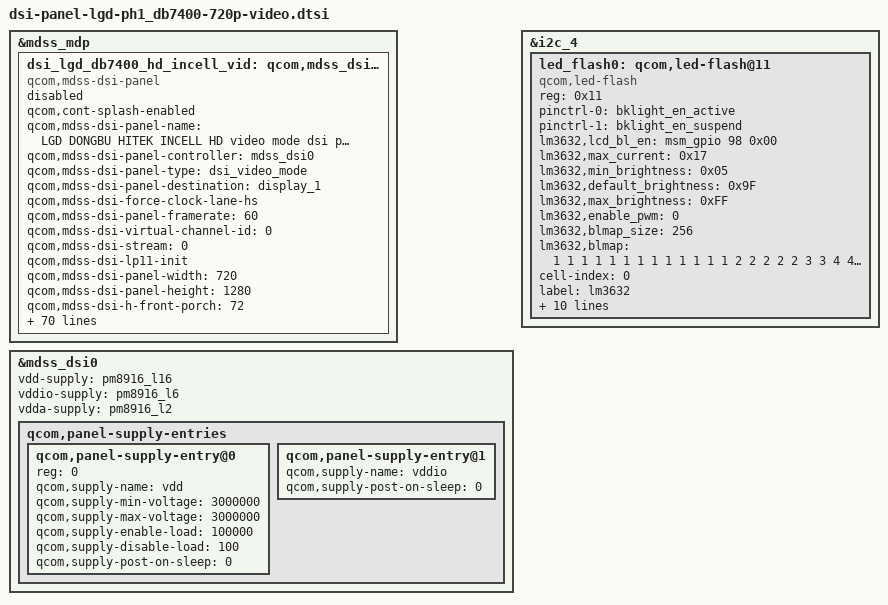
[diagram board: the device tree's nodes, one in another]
&mdss_mdp {
	dsi_lgd_db7400_hd_incell_vid: qcom,mdss_dsi_lgd_incell_db7400_hd_video{
		compatible = "qcom,mdss-dsi-panel";
		status = "disable";
		qcom,cont-splash-enabled;
		qcom,mdss-dsi-panel-name = "LGD DONGBU HITEK INCELL HD video mode dsi panel";
		qcom,mdss-dsi-panel-controller = <&mdss_dsi0>;
		qcom,mdss-dsi-panel-type = "dsi_video_mode";
		qcom,mdss-dsi-panel-destination = "display_1";
		qcom,mdss-dsi-force-clock-lane-hs;
		qcom,mdss-dsi-panel-framerate = <60>;
		qcom,mdss-dsi-virtual-channel-id = <0>;
		qcom,mdss-dsi-stream = <0>;
		qcom,mdss-dsi-lp11-init;
		qcom,mdss-dsi-panel-width = <720>;
		qcom,mdss-dsi-panel-height = <1280>;
		qcom,mdss-dsi-h-front-porch = <72>;
		qcom,mdss-dsi-h-back-porch = <120>;
		qcom,mdss-dsi-h-pulse-width = <4>;
		qcom,mdss-dsi-h-sync-skew = <0>;
		qcom,mdss-dsi-v-front-porch = <580>;
		qcom,mdss-dsi-v-back-porch = <11>;
		qcom,mdss-dsi-v-pulse-width = <1>;
		qcom,mdss-dsi-h-left-border = <0>;
		qcom,mdss-dsi-h-right-border = <0>;
		qcom,mdss-dsi-v-top-border = <0>;
		qcom,mdss-dsi-v-bottom-border = <0>;
		qcom,mdss-pan-physical-width-dimension = < 71 >;
		qcom,mdss-pan-physical-height-dimension = < 126 >;
		qcom,mdss-dsi-bpp = <24>;
		qcom,mdss-dsi-color-order = "rgb_swap_rgb";
		qcom,mdss-dsi-underflow-color = <0>;
		qcom,mdss-dsi-border-color = <0>;

		/* DB7400 CUT5 Initial code start */
		qcom,mdss-dsi-on-command-cut5 = [
			15 01 00 00 00 00 02 /*address*/
			36 00

			15 01 00 00 00 00 02 /*manufacturer*/
			B0 00

			29 01 00 00 00 00 03 /*RGB interface*/
			B1 00 30

			29 01 00 00 00 00 07 /*module charateristic set*/
			B2 50 00 0C 00 00 00

			29 01 00 00 00 00 05 /*internal timgin set*/
			B3 4F 80 32 56

			29 01 00 00 00 00 07/*channel control*/
			B4 05 04 02 00 11 00

			29 01 00 00 00 00 34 /*GIP Control Set*/
			B5 19 04 1C 22 2F 80
			2F 1F 04 40 05 00 20
			09 04 40 05 00 A5 0D
			2F 28 3F FF 3F FF 01
			7C 00 02 50 23 40 15
			6C CB BA A9 97 8D 1F
			23 40 15 6C CB BA A9
			97 8D 1F

			29 01 00 00 00 00 03 /*touch enable*/
			B6 01 01

			29 01 00 00 00 00 04 /*gvddp*/
			B7 00 3C 3E

			29 01 00 00 00 00 03 /*vcom*/
			BA 00 43

			29 01 00 00 00 00 10 /*vghl*/
			BB 00 94 8B 00 00 00
			00 00 00 00 00 00 00
			00 13

			29 01 00 00 00 00 03
			BD 04 33

			15 01 00 00 00 00 02 /*vci1*/
			BE 44

			29 01 00 00 00 00 07 /*write dsi control*/
			95 00 08 10 00 00 00

			29 01 00 00 00 00 03 /*mipi parameter setting*/
			C6 0A 00

			29 01 00 00 00 00 02 /*add temp*/
			CF 07

			29 01 00 00 00 00 1B /*touch gip control*/
			D7 01 13 FF 39 0B 04
			14 F4 01 00 00 00 00
			40 01 57 57 2F 28 28
			50 00 00 00 00 00

			29 01 00 00 00 00 06
			F5 00 06 00 00 80

			29 01 00 00 00 00 02 /*vdd1 regulator*/
			F6 06

			29 01 00 00 00 00 04/*sharpness enhance*/
			81 18 34 00

			29 01 00 00 00 00 22/*contrast enhance*/
			83 10 00 07 0F 17 1F
			27 2F 37 3F 47 4F 57
			5F 67 6F 77 7F 87 8F
			97 9F A7 AF B7 BF C7
			CF D7 DF E7 EF F5

			29 01 00 00 00 00 24/*power sequence control*/
			F0 18 00 00 14 00 00
			00 01 00 03 2B 01 02
			53 58 5D 62 A6 AB B0
			B0 B0 AF B0 AD 85 B0
			B0 5D 58 53 4E 0A 05
			00

			29 01 00 00 00 00 0A /*pos gamma curve red*/
			D0 63 04 72 03 00 00
			42 01 02

			29 01 00 00 00 00 0A /*neg gamma curve red*/
			D1 62 03 73 02 00 00
			42 12 01

			29 01 00 00 00 00 0A /*pos gamma curve green*/
			D2 53 04 72 03 00 00
			42 01 02

			29 01 00 00 00 00 0A /*neg gamma curve green*/
			D3 52 03 73 02 00 00
			42 12 01

			29 01 00 00 00 00 0A /*pos gamma curve blue*/
			D4 53 04 72 03 00 00
			42 01 02

			29 01 00 00 3C 00 0A /*neg gamma curve blue*/
			D5 52 03 73 02 00 00
			42 12 01

			05 01 00 00 A0 00 01 /*exit sleep*/
			11

			05 01 00 00 28 00 01 /*display on*/
			29

		];

		qcom,mdss-dsi-off-command1-cut5 = [
			05 01 00 00 28 00 01 /*display off*/
			28
			05 01 00 00 28 00 01 /*Sleep in*/
			10
		];
		qcom,mdss-dsi-off-command2-cut5 = [
			29 01 00 00 00 00 1C /*34->1C GIP Control Set*/
			B5 19 04 1C 22 2F 80
			2F 1F 04 40 05 00 20
			09 04 40 05 00 A5 0D
			2F 1F 04 00 04 00 00
			29 01 00 00 00 00 03 /*touch enable*/
			B6 01 01

			29 01 00 00 00 00 02 /*add temp*/
			CF 07

			29 01 00 00 00 00 1B /*touch gip control*/
			D7 01 13 FF 39 0B 04
			14 F4 01 00 00 00 00
			40 01 67 67 47 10 10
			34 00 00 00 00 00

			29 01 00 00 00 00 06/*Touch LFD Control set*/
			F5 00 06 00 00 C0

			29 01 00 00 5A 00 03 /*mipi lane floating*/
			C8 01 00
		];
		/* DB7400 CUT5 initial code end */

		/* DB7400 CUT6 initial code start */
		qcom,mdss-dsi-on-command-cut6 = [
			15 01 00 00 00 00 02 /*address*/
			36 00

			15 01 00 00 00 00 02 /*manufacturer*/
			B0 00

			29 01 00 00 00 00 03 /*RGB interface*/
			B1 00 30

			29 01 00 00 00 00 07 /*module charateristic set*/
			B2 50 00 0C 00 00 00

			29 01 00 00 00 00 05 /*internal timgin set*/
			B3 4F 80 32 56

			29 01 00 00 00 00 07/*channel control*/
			B4 05 04 0A 00 11 00

			29 01 00 00 00 00 37 /*GIP Control Set*/
			B5 19 04 1C 22 2F 80
			2F 1F 04 40 05 05 00
			20 09 04 40 05 05 00
			A5 0D 2F 28 3F FF 3F
			FF 01 7C 00 03 78 23
			40 15 6C CB BA A9 97
			8D 1F 23 40 15 6C CB
			BA A9 97 8D 1F 00

			29 01 00 00 00 00 03 /*touch enable*/
			B6 01 01

			29 01 00 00 00 00 04 /*gvddp*/
			B7 00 3C 3E

			29 01 00 00 00 00 03 /*vcom*/
			BA 00 43

			29 01 00 00 00 00 10 /*vghl*/
			BB 00 94 8B 00 00 00
			00 00 00 00 00 00 00
			00 13

			29 01 00 00 00 00 03 /*Bias current*/
			BD 03 31

			15 01 00 00 00 00 02 /*vci1*/
			BE 44

			29 01 00 00 00 00 07 /*write dsi control*/
			95 00 08 10 00 00 00

			29 01 00 00 00 00 03 /*mipi parameter setting*/
			C6 08 00

			29 01 00 00 00 00 02 /*add temp*/
			CF 07

			29 01 00 00 00 00 1B /*touch gip control*/
			D7 00 03 FF 00 00 04
			14 CC 01 00 00 00 00
			40 01 57 57 16 28 28
			69 00 00 00 00 00

			15 01 00 00 00 00 02 /*Contrast of*/
			83 00

			39 01 00 00 00 00 2F /*ief 1*/
			77 03 00 00 00 11 05
			10 d1 0b 20 ee 05 20
			b2 18 30 11 05 50 d1
			0b 60 b2 18 70 b2 18
			70 b2 18 70 b2 18 70
			b2 18 70 b2 18 70 b2
			18 70 b2 18 70

			39 01 00 00 00 00 42 /*ief 2*/
			78 25 29 ff fd e1 5f
			91 fe db ff fb 2d 01
			25 81 3e 03 e0 bf 10
			03 d8 1f 09 c3 00 1d
			71 ff fd db 8f 91 fe
			77 e0 f6 2d 01 25 29
			ff fd e1 5f 91 fe db
			ff fb 2d 01 25 29 ff
			fd e1 5f 91 fe db ff
			fb 2d 01

			39 01 00 00 00 00 42 /*ief 3*/
			79 25 29 ff fd e1 5f
			91 fe db ff fb 2d 01
			25 29 ff fd e1 5f 91
			fe db ff fb 2d 01 25
			29 ff fd e1 5f 91 fe
			db ff fb 2d 01 25 29
			ff fd e1 5f 91 fe db
			ff fb 2d 01 25 29 ff
			fd e1 5f 91 fe db ff
			fb 2d 01

			39 01 00 00 00 00 46 /*ief 4*/
			7a 25 29 ff fd e1 5f
			91 fe db ff fb 2d 01
			25 29 ff fd e1 5f 91
			fe db ff fb 2d 01 25
			29 ff fd e1 5f 91 fe
			db ff fb 2d 01 25 29
			ff fd e1 5f 91 fe db
			ff fb 2d 01 00 00 00
			00 00 00 00 00 00 00
			00 00 00 80 00 00 00

			29 01 00 00 00 00 06 /*DB Check need*/
			F5 00 06 00 00 80

			29 01 00 00 00 00 02 /*vdd1 regulator*/
			F6 06

			29 01 00 00 00 00 24/*power sequence control*/
			F0 18 00 00 14 00 00
			00 01 00 03 2B 01 02
			53 58 5D 62 A6 AB B0
			B0 B0 AF B0 AD 85 B0
			B0 5D 58 53 4E 0A 05
			00

			29 01 00 00 00 00 0A /*pos gamma curve red*/
			D0 63 04 72 03 00 00
			42 01 02

			29 01 00 00 00 00 0A /*neg gamma curve red*/
			D1 62 03 73 02 00 00
			42 12 01

			29 01 00 00 00 00 0A /*pos gamma curve green*/
			D2 53 04 72 03 00 00
			42 01 02

			29 01 00 00 00 00 0A /*neg gamma curve green*/
			D3 52 03 73 02 00 00
			42 12 01

			29 01 00 00 00 00 0A /*pos gamma curve blue*/
			D4 53 04 72 03 00 00
			42 01 02

			29 01 00 00 3C 00 0A /*neg gamma curve blue*/
			D5 52 03 73 02 00 00
			42 12 01

			05 01 00 00 A0 00 01 /*exit sleep*/
			11

			05 01 00 00 28 00 01 /*display on*/
			29

		];
		qcom,mdss-dsi-off-command1-cut6 = [
			05 01 00 00 28 00 01 /*display off*/
			28
			05 01 00 00 28 00 01 /*Sleep in*/
			10
		];
		qcom,mdss-dsi-off-command2-cut6 = [
			29 01 00 00 00 00 1E /*34->1C GIP Control Set*/
			B5 19 04 1C 22 2F 80
			2F 1F 04 40 05 05 00
			20 09 04 40 05 05 00
			A5 0D 2F 1F 04 00 04
			00 00

			29 01 00 00 00 00 06/*Touch LFD Control set*/
			F5 00 06 00 00 C0

			29 01 00 00 5A 00 03 /*mipi lane floating*/
			C8 01 00
		];
		/* DB7400 CUT6 initial code end */

		/* DB7400 CUT7 initial code start */
		qcom,mdss-dsi-on-command = [
			15 01 00 00 00 00 02 /*address*/
			36 00

			15 01 00 00 00 00 02 /*manufacturer*/
			B0 00

			29 01 00 00 00 00 03 /*RGB interface*/
			B1 00 30

			29 01 00 00 00 00 07 /*module charateristic set*/
			B2 50 00 0C 00 00 00

			29 01 00 00 00 00 05 /*internal timgin set*/
			B3 4F 80 32 56

			29 01 00 00 00 00 07/*channel control*/
			B4 05 04 0A 00 11 00

			29 01 00 00 00 00 37 /*GIP Control Set*/
			B5 19 04 1C 22 2F 80
			2F 1F 04 40 05 05 00
			20 09 04 40 05 05 00
			A5 0D 2F 28 3F FF 3F
			FF 01 7C 00 03 78 23
			40 15 6C CB BA A9 97
			8D 1F 23 40 15 6C CB
			BA A9 97 8D 1F 00

			29 01 00 00 00 00 03 /*touch enable*/
			B6 01 01

			29 01 00 00 00 00 04 /*gvddp*/
			B7 00 3C 3E

			29 01 00 00 00 00 03 /*vcom*/
			BA 00 43

			29 01 00 00 00 00 10 /*vghl*/
			BB 00 94 8B 00 00 00
			00 00 00 00 00 00 00
			00 13

			29 01 00 00 00 00 03 /*Bias current*/
			BD 03 31

			15 01 00 00 00 00 02 /*vci1*/
			BE 44

			29 01 00 00 00 00 07 /*write dsi control*/
			95 00 08 10 00 00 00

			29 01 00 00 00 00 03 /*mipi parameter setting*/
			C6 08 00

			29 01 00 00 00 00 02 /*add temp*/
			CF 07

			29 01 00 00 00 00 1B /*touch gip control*/
			D7 00 03 FF 00 00 04
			14 CC 01 00 00 00 00
			40 01 57 57 16 28 28
			69 00 00 00 00 00

			15 01 00 00 00 00 02 /*Contrast of*/
			83 00

			39 01 00 00 00 00 2F /*ief 1*/
			77 03 00 00 00 11 05
			10 d1 0b 20 ee 05 20
			b2 18 30 11 05 50 d1
			0b 60 b2 18 70 b2 18
			70 b2 18 70 b2 18 70
			b2 18 70 b2 18 70 b2
			18 70 b2 18 70

			39 01 00 00 00 00 42 /*ief 2*/
			78 25 29 ff fd e1 5f
			91 fe db ff fb 2d 01
			25 81 3e 03 e0 bf 10
			03 d8 1f 09 c3 00 1d
			71 ff fd db 8f 91 fe
			77 e0 f6 2d 01 25 29
			ff fd e1 5f 91 fe db
			ff fb 2d 01 25 29 ff
			fd e1 5f 91 fe db ff
			fb 2d 01

			39 01 00 00 00 00 42 /*ief 3*/
			79 25 29 ff fd e1 5f
			91 fe db ff fb 2d 01
			25 29 ff fd e1 5f 91
			fe db ff fb 2d 01 25
			29 ff fd e1 5f 91 fe
			db ff fb 2d 01 25 29
			ff fd e1 5f 91 fe db
			ff fb 2d 01 25 29 ff
			fd e1 5f 91 fe db ff
			fb 2d 01

			39 01 00 00 00 00 46 /*ief 4*/
			7a 25 29 ff fd e1 5f
			91 fe db ff fb 2d 01
			25 29 ff fd e1 5f 91
			fe db ff fb 2d 01 25
			29 ff fd e1 5f 91 fe
			db ff fb 2d 01 25 29
			ff fd e1 5f 91 fe db
			ff fb 2d 01 00 00 00
			00 00 00 00 00 00 00
			00 00 00 80 00 00 00

			29 01 00 00 00 00 06 /* sharpness_control */
			81 00 22 00 04 04

			29 01 00 00 00 00 06 /*DB Check need*/
			F5 00 06 00 00 80

			29 01 00 00 00 00 02 /*vdd1 regulator*/
			F6 06

			29 01 00 00 00 00 24/*power sequence control*/
			F0 18 00 00 14 00 00
			00 01 00 03 2B 01 02
			53 58 5D 62 A6 AB B0
			B0 B0 AF B0 AD 85 B0
			B0 5D 58 53 4E 0A 05
			00

			29 01 00 00 00 00 0A /*pos gamma curve red*/
			D0 63 04 72 03 00 00
			42 01 02

			29 01 00 00 00 00 0A /*neg gamma curve red*/
			D1 62 03 73 02 00 00
			42 12 01

			29 01 00 00 00 00 0A /*pos gamma curve green*/
			D2 53 04 72 03 00 00
			42 01 02

			29 01 00 00 00 00 0A /*neg gamma curve green*/
			D3 52 03 73 02 00 00
			42 12 01

			29 01 00 00 00 00 0A /*pos gamma curve blue*/
			D4 53 04 72 03 00 00
			42 01 02

			29 01 00 00 3C 00 0A /*neg gamma curve blue*/
			D5 52 03 73 02 00 00
			42 12 01

			05 01 00 00 A0 00 01 /*exit sleep*/
			11

			05 01 00 00 28 00 01 /*display on*/
			29

		];
		qcom,mdss-dsi-off-command1 = [
			05 01 00 00 28 00 01 /*display off*/
			28
			05 01 00 00 28 00 01 /*Sleep in*/
			10
		];
		qcom,mdss-dsi-off-command2 = [
			29 01 00 00 00 00 1E /*34->1C GIP Control Set*/
			B5 19 04 1C 22 2F 80
			2F 1F 04 40 05 05 00
			20 09 04 40 05 05 00
			A5 0D 2F 1F 04 00 04
			00 00

			29 01 00 00 00 00 06/*Touch LFD Control set*/
			F5 00 06 00 00 C0

			29 01 00 00 5A 00 03 /*mipi lane floating*/
			C8 01 00
		];
		/* DB7400 CUT7 initial code end */

		/* reader mode command start */
		qcom,panel-reader-mode-step1-command = [
			29 01 00 00 00 00 0E /* reader mode 1 */
			89 10 FF FF E9 00 00
			00 FF FF DE 00 00 00
		];
		qcom,panel-reader-mode-step2-command = [
			29 01 00 00 00 00 0E /* reader mode 2 */
			89 10 FF FF DE 00 00
			00 FF FF DE 00 00 00
		];
		qcom,panel-reader-mode-step3-command = [
			29 01 00 00 00 00 0E /* reader mode 3 */
			89 10 FF FF CE 00 00
			00 FF FF DE 00 00 00
		];

		qcom,panel-reader-mode-off-command = [
			29 01 00 00 00 00 02 /* reader mode off */
			89 00
		];
		qcom,panel-reader-mode-mono-enable-command = [
			39 01 00 00 00 00 2F /*ief 1*/
			77 03 00 00 00 11 05
			10 D1 0B 20 EE 05 20
			B2 18 30 11 05 50 D1
			0B 60 B2 18 70 B2 18
			70 B2 18 70 B2 18 70
			B2 18 70 B2 18 70 B2
			18 70 B2 18 70

			39 01 00 00 00 00 42 /*ief 2*/
			78 59 B0 44 07 9C 60
			89 0E 98 C0 12 1D 00
			59 90 85 00 9C 90 89
			0D 98 60 08 71 00 63
			60 44 07 9C 50 89 0E
			18 C0 16 1D 00 4C 18
			45 07 98 70 89 0E 34
			E1 0D 1D 00 4C 18 45
			07 98 70 89 0E 34 E1
			0D 1D 00

			39 01 00 00 00 00 42 /*ief 3*/
			79 4D B0 84 0A 9A 60
			09 0F 30 C1 12 F7 07
			4D B0 84 0A 9A 60 09
			0F 30 C1 12 F7 07 4D
			B0 84 0A 9A 60 09 0F
			30 C1 12 F7 07 4D B0
			84 0A 9A 60 09 0F 30
			C1 12 F7 07 4D B0 84
			0A 9A 60 09 0F 30 C1
			12 F7 07

			39 01 00 00 00 00 46 /*ief 4*/
			7A 4D B0 84 0A 9A 60
			09 0F 30 C1 12 F7 07
			4D B0 84 0A 9A 60 09
			0F 30 C1 F7 07 00 4D
			B0 84 0A 9A 60 09 0F
			30 C1 12 F7 07 4D B0
			84 0A 9A 60 09 0F 30
			C1 12 F7 07 00 00 00
			00 00 00 00 00 00 00
			00 00 00 80 00 00 00
		];
		qcom,panel-reader-mode-mono-disable-command = [
			39 01 00 00 00 00 2F /*ief 1*/
			77 03 00 00 00 11 05
			10 d1 0b 20 ee 05 20
			b2 18 30 11 05 50 d1
			0b 60 b2 18 70 b2 18
			70 b2 18 70 b2 18 70
			b2 18 70 b2 18 70 b2
			18 70 b2 18 70

			39 01 00 00 00 00 42 /*ief 2*/
			78 25 29 ff fd e1 5f
			91 fe db ff fb 2d 01
			25 81 3e 03 e0 bf 10
			03 d8 1f 09 c3 00 1d
			71 ff fd db 8f 91 fe
			77 e0 f6 2d 01 25 29
			ff fd e1 5f 91 fe db
			ff fb 2d 01 25 29 ff
			fd e1 5f 91 fe db ff
			fb 2d 01

			39 01 00 00 00 00 42 /*ief 3*/
			79 25 29 ff fd e1 5f
			91 fe db ff fb 2d 01
			25 29 ff fd e1 5f 91
			fe db ff fb 2d 01 25
			29 ff fd e1 5f 91 fe
			db ff fb 2d 01 25 29
			ff fd e1 5f 91 fe db
			ff fb 2d 01 25 29 ff
			fd e1 5f 91 fe db ff
			fb 2d 01

			39 01 00 00 00 00 46 /*ief 4*/
			7a 25 29 ff fd e1 5f
			91 fe db ff fb 2d 01
			25 29 ff fd e1 5f 91
			fe db ff fb 2d 01 25
			29 ff fd e1 5f 91 fe
			db ff fb 2d 01 25 29
			ff fd e1 5f 91 fe db
			ff fb 2d 01 00 00 00
			00 00 00 00 00 00 00
			00 00 00 80 00 00 00
		];
		/* reader mode command end */

		qcom,mdss-dsi-on-command-state = "dsi_lp_mode";
		qcom,mdss-dsi-off-command-state = "dsi_hs_mode";
		qcom,mdss-dsi-off-command2-state = "dsi_lp_mode";
		qcom,mdss-dsi-reader_mode-command-state = "dsi_hs_mode";
		qcom,mdss-dsi-h-sync-pulse = <0>;
		qcom,mdss-dsi-traffic-mode = "non_burst_sync_event";
		qcom,mdss-dsi-lane-map = "lane_map_0123";
		qcom,mdss-dsi-bllp-eof-power-mode;
		//qcom,mdss-dsi-bllp-power-mode;
		qcom,mdss-dsi-last-line-interleave;
		qcom,mdss-dsi-lane-0-state;
		qcom,mdss-dsi-lane-1-state;
		qcom,mdss-dsi-lane-2-state;
		qcom,mdss-dsi-lane-3-state;
		qcom,mdss-dsi-panel-timings = [A8 26 1A 00 50 4A 28 2A 3E 03 04 00];
		qcom,mdss-dsi-t-clk-post = <0x03>;
		qcom,mdss-dsi-t-clk-pre = <0x24>;
		qcom,mdss-dsi-bl-min-level = <1>;
		qcom,mdss-dsi-bl-max-level = <255>;
		qcom,mdss-dsi-dma-trigger = "trigger_sw";
		qcom,mdss-dsi-mdp-trigger = "none";
		qcom,mdss-dsi-reset-sequence = <1 5>;
	};
};

&mdss_dsi0 {
    vdd-supply = <&pm8916_l16>;
    vddio-supply = <&pm8916_l6>;
    vdda-supply = <&pm8916_l2>;
    qcom,panel-supply-entries {
        qcom,panel-supply-entry@0 {
            reg = <0>;
            qcom,supply-name = "vdd";
            qcom,supply-min-voltage = <3000000>;
            qcom,supply-max-voltage = <3000000>;
            qcom,supply-enable-load = <100000>;
            qcom,supply-disable-load = <100>;
            qcom,supply-post-on-sleep = <0>;
        };
        qcom,panel-supply-entry@1 {
            qcom,supply-name = "vddio";
            qcom,supply-post-on-sleep = <0>;
        };
    };
};

&i2c_4 {
	led_flash0: qcom,led-flash@11 {
		compatible                = "qcom,led-flash";
		status                    = "ok";
		reg                       = <0x11>;

		pinctrl-names = "default", "sleep";
		pinctrl-0 = <&bklight_en_active>;
		pinctrl-1 = <&bklight_en_suspend>;

		lm3632,lcd_bl_en = <&msm_gpio 98 0x00>;
		lm3632,max_current = <0x17>;
		lm3632,min_brightness = <0x05>;
		lm3632,default_brightness = <0x9F>;
		lm3632,max_brightness = <0xFF>;
		lm3632,enable_pwm = <0>;
		lm3632,blmap_size = <256>;
		lm3632,blmap = <
		    /* 0  */	1  	1  	1  	1  	1  	1  	1  	1  	1  	1
			/* 10 */	1  	1  	1  	2  	2  	2  	2  	2  	3  	3
			/* 20 */	4  	4  	4  	5  	5  	5  	5	5	5	5
			/* 30 */	5	5	5	5	5	5	5	5	5	5
			/* 40 */	5	5	5	5	5	5	5	5	5	5
			/* 50 */	5	6  	6  	6	6	6	6	6	7	7
			/* 60 */	7	7  	7	7	8	8	8	8	8	9
			/* 70 */	9	9	9	10	10	10	11	11	11	12
			/* 80 */	12	12	13	13	13	14	14	15	15	16
			/* 90 */	16	17	17	18	18	19	19	19	20	20
			/* 100 */	21	21	22	22	23	23	24	24	25 	25
			/* 110 */	25	26	26	27	27	28	28	29	29	30
			/* 120 */	30	31	31	32	32	33	33	34	34	35
			/* 130 */	36	37	38	39	40	41	42	43	44	45
			/* 140 */	46	47	47	47	48	48	49	50	51	52
			/* 150 */	53	54	55	55	56 	56	57	57	58	58
			/* 160 */	59	60	61	62	63	64	65	66	67	68
			/* 170 */	69	70	71	72	73	74	75	76	77	78
			/* 180 */	79	80	81	82	83	84	85	86	87	88
			/* 190 */	89	90	91	92	93	94	95	96	97	99
			/* 200 */	101	103	104	105	106	107	108	109	110	111
			/* 210 */	112	113	114	115	117	119	121	123	125	126
			/* 220 */	127	129	131	135	137	139	141	143	143	144
			/* 230 */	144	145	145	147	149	151	153	155	157	159
			/* 240 */	161	162	163	164	165	165	167	169	171	173
			/* 250 */	175	177	179	182	185	187	>;

		cell-index = <0>;
		label                   = "lm3632";
		qcom,flash-name         = "lm3632";
		qcom,slave-id           = <0x11 0x01 0x01>;
		qcom,flash-type         = <1>;              // LED_FLASH
		qcom,gpio-no-mux        = <0>;
		gpios                   = <&msm_gpio 31 0>; // FLASH_STROBE_TRIG, GPIO 31
		qcom,gpio-flash-en      = <0>;
		qcom,gpio-req-tbl-num   = <0>;
		qcom,gpio-req-tbl-flags = <0>;
		qcom,gpio-req-tbl-label = "FLASH_EN";
		qcom,cci-master = <0>;
	};
};
